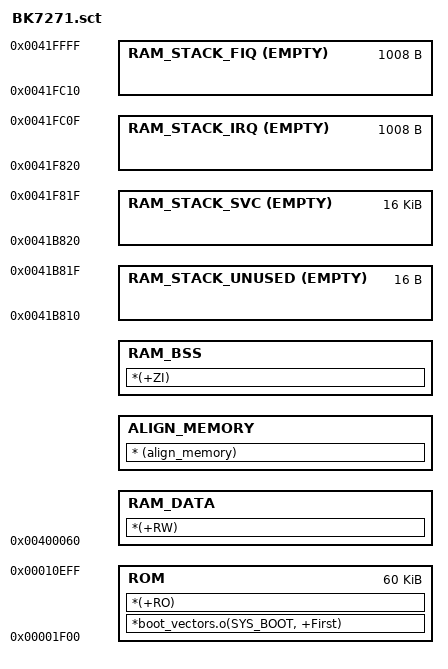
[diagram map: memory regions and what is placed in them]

;/* the internal SRAM */
;rom (wx) : ORIGIN = 0x0, LENGTH = 128K
;ram (wx) : ORIGIN = 0x400000, LENGTH = 128K
;
;/* the shared RAM */
;sharedram (rw!x) : ORIGIN = 0x10000000, LENGTH = 256K
;
;/* Fake LA memory */
;lamac_memory (!rx) : org = 0x11000000, len = 1024K
;laphy_memory (!rx) : org = 0x11800000, len = 1024K
;
;/* the MACHW MIB location */
;machw_mib_loc (rw!x) : ORIGIN = 0x10B00800, LENGTH = 1K

SECTIONS 0x001f00 (1024 * 60)
{
    ROM  0x001f00 (1024 * 60)
    {
        *boot_vectors.o(SYS_BOOT, +First)		
		
        *(+RO)
    } 
    
    ;RAM_VECTOR 0x400000 EMPTY 0x20
    ;{
    ;}
    
    RAM_DATA  0x400060
    {
        *(+RW)
    } 
   
    ALIGN_MEMORY +0 ALIGNALL 32
    {
		* (align_memory)
    }
    
    RAM_BSS  +0
    {
        *(+ZI)
    } 
	

    RAM_STACK_UNUSED 0x420000 - 0x3F0 - 0x3F0 - 0x4000 - 0x10  EMPTY 0x10
    {
    } 

    RAM_STACK_SVC 0x420000 - 0x3F0 - 0x3F0 - 0x4000  EMPTY 0x4000
    {
    } 

    RAM_STACK_IRQ 0x420000 - 0x3F0 - 0x3F0  EMPTY 0x3F0
    {
    } 

    RAM_STACK_FIQ 0x420000 - 0x3F0 EMPTY 0x3F0
    {
    }
    

}

